# STM32H5F4xx register map
File version: 1.0
Registers are 32-bit, read-write, reset 0x0 unless marked. A register's access mark holds for its fields unless they carry their own. Offsets are from the block's base; [hi:lo] are bit positions; {n}, {i} and the like mark numbered series; 'fields as' and 'values as' point back to an identical list.

## OTFDEC2
Base 0x46005400
Same registers: OTFDEC2_S 0x56005400
0x00 CR — OTFDEC Control register
  [0] ENC — Encryption mode bit
0x10 PRIVCFGR — OTFDEC Privileged access control Configuration register
  [0] PRIV — Privileged access protection
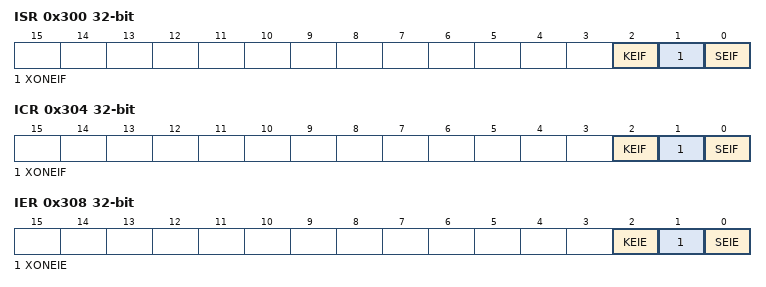
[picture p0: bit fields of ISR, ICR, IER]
0x300 ISR — OTFDEC Interrupt Status register
  [2] KEIF — Key Error Interrupt Flag status bit before enable (mask)
  [1] XONEIF — Execute-only Error Interrupt Flag status bit before enable (mask)
  [0] SEIF — Security Error Interrupt Flag status bit before enable (mask)
0x304 ICR — OTFDEC Interrupt Clear register
  [2] KEIF — Key Error Interrupt Flag clear bit
  [1] XONEIF — Execute-only Error Interrupt Flag clear bit
  [0] SEIF — Security Error Interrupt Flag clear bit
0x308 IER — OTFDEC Interrupt Enable register
  [2] KEIE
  [1] XONEIE — Execute-only Error Interrupt Enable bit
  [0] SEIE — Security Error Interrupt Enable bit

## DLYB_SDMMC1 — Delay Block DLYB
Base 0x46008400
Same registers: DLYB_SDMMC2 0x46008800, DLYB_OCTOSPI1 0x4600F000, DLYB_OCTOSPI2 0x4600F400, DLYB_SDMMC1_S 0x56008400, DLYB_SDMMC2_S 0x56008800, DLYB_OCTOSPI1_S 0x5600F000, DLYB_OCTOSPI2_S 0x5600F400
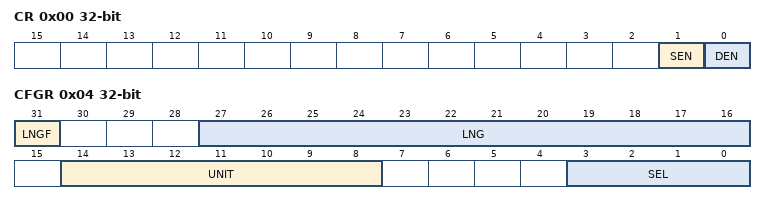
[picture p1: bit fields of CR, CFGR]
0x00 CR — DELAY BLOCK control register
  [1] SEN — Sampler length enable
  [0] DEN — Delay Block enable
0x04 CFGR — DELAY BLOCK configuration register
  [31] LNGF — Length valid flag
  [27:16] LNG — Delay line length value[11:0]
  [14:8] UNIT — Delay Defines the delay of a Unit delay cell[6:0]
  [3:0] SEL — Select the phase for the Output clock[3:0]

## FMC_Bank1_R — Flexible Memory Controller
Base 0x47000400
Same registers: FMC_Bank1_R_S 0x57000400
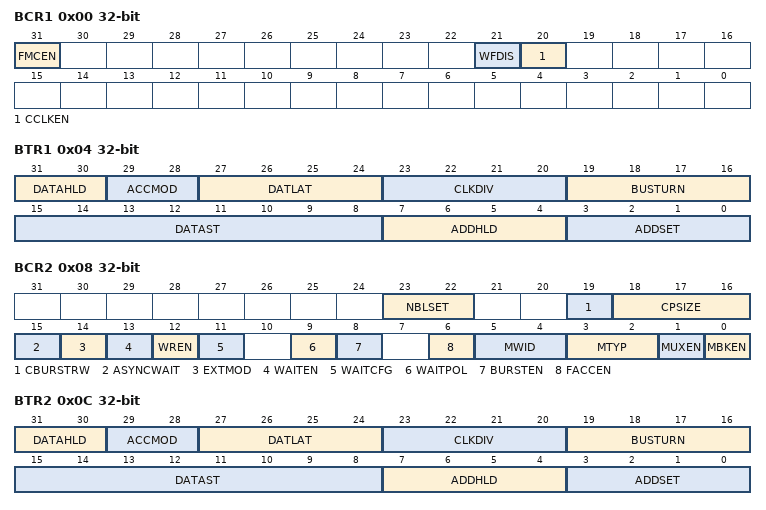
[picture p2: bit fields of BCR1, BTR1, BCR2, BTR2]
0x00 BCR1 — NOR/PSRAM chip-select control register(BCR) and chip-select timing register(BTR)
  [31] FMCEN — FMC controller Enable
  [21] WFDIS — Write FIFO Disable
  [20] CCLKEN — Continuous clock enable
0x04 BTR1 — NOR/PSRAM chip-select control register(BCR) and chip-select timing register(BTR)
  [31:30] DATAHLD — DATAHLD[1:0] bits (Data hold phase duration)
  [29:28] ACCMOD — ACCMOD[1:0] bits (Access mode)
  [27:24] DATLAT — DATLA[3:0] bits (Data latency)
  [23:20] CLKDIV — CLKDIV[3:0] bits (Clock divide ratio)
  [19:16] BUSTURN — BUSTURN[3:0] bits (Bus turnaround phase duration)
  [15:8] DATAST — DATAST [3:0] bits (Data-phase duration)
  [7:4] ADDHLD — ADDHLD[3:0] bits (Address-hold phase duration)
  [3:0] ADDSET — ADDSET[3:0] bits (Address setup phase duration)
0x08 BCR2 — NOR/PSRAM chip-select control register(BCR) and chip-select timing register(BTR)
  [23:22] NBLSET — Byte lane (NBL) setup
  [19] CBURSTRW — Write burst enable
  [18:16] CPSIZE — PSIZE[2:0] bits CRAM Page Size
  [15] ASYNCWAIT — Asynchronous wait
  [14] EXTMOD — Extended mode enable
  [13] WAITEN — Wait enable bit
  [12] WREN — Write enable bit
  [11] WAITCFG — Wait timing configuration
  [9] WAITPOL — Wait signal polarity bit
  [8] BURSTEN — Burst enable bit
  [6] FACCEN — Flash access enable
  [5:4] MWID — MWID[1:0] bits (Memory data bus width)
  [3:2] MTYP — MTYP[1:0] bits (Memory type)
  [1] MUXEN — Address/data multiplexing enable bit
  [0] MBKEN — Memory bank enable bit
0x0C BTR2 — NOR/PSRAM chip-select control register(BCR) and chip-select timing register(BTR)
  fields as BTR1
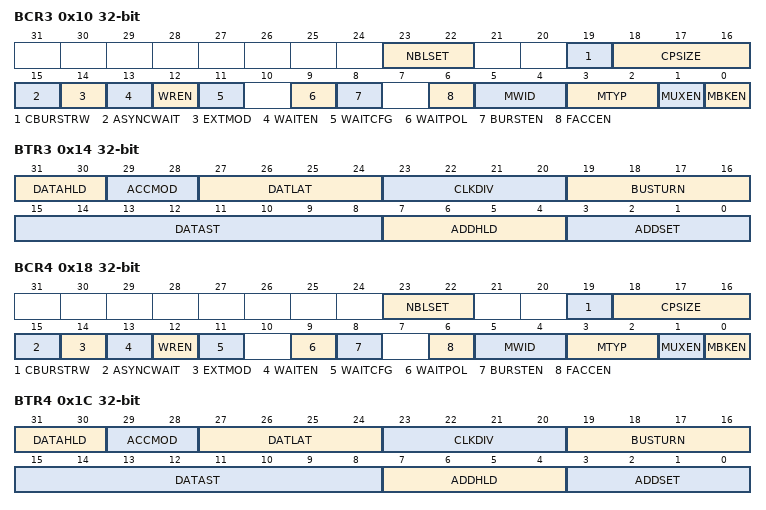
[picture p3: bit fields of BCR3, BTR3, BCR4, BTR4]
0x10 BCR3 — NOR/PSRAM chip-select control register(BCR) and chip-select timing register(BTR)
  fields as BCR2
0x14 BTR3 — NOR/PSRAM chip-select control register(BCR) and chip-select timing register(BTR)
  fields as BTR1
0x18 BCR4 — NOR/PSRAM chip-select control register(BCR) and chip-select timing register(BTR)
  fields as BCR2
0x1C BTR4 — NOR/PSRAM chip-select control register(BCR) and chip-select timing register(BTR)
  fields as BTR1
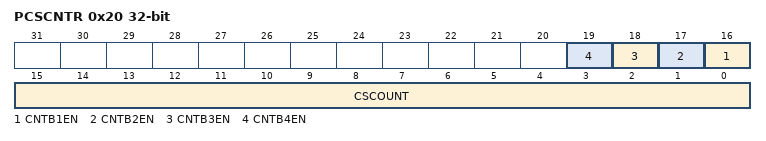
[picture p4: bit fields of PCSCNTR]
0x20 PCSCNTR — PSRAM chip-select counter register
  [n+15] CNTB{n}EN (n=1..4) — Counter PSRAM/NOR Bank1_{n} enable
  [15:0] CSCOUNT — CSCOUNT[15:0] bits (Chip select counter)
